# GD32E51x_CL register map
File version: 1.0
CPU: CM33 r0p4, little endian, MPU, FPU, 4 interrupt priority bits
Registers are 32-bit, read-write, reset 0x0 unless marked. A register's access mark holds for its fields unless they carry their own. Offsets are from the block's base; [hi:lo] are bit positions; {n}, {i} and the like mark numbered series; 'fields as' and 'values as' point back to an identical list.

## EXMC — External memory controller
Base 0xA0000000
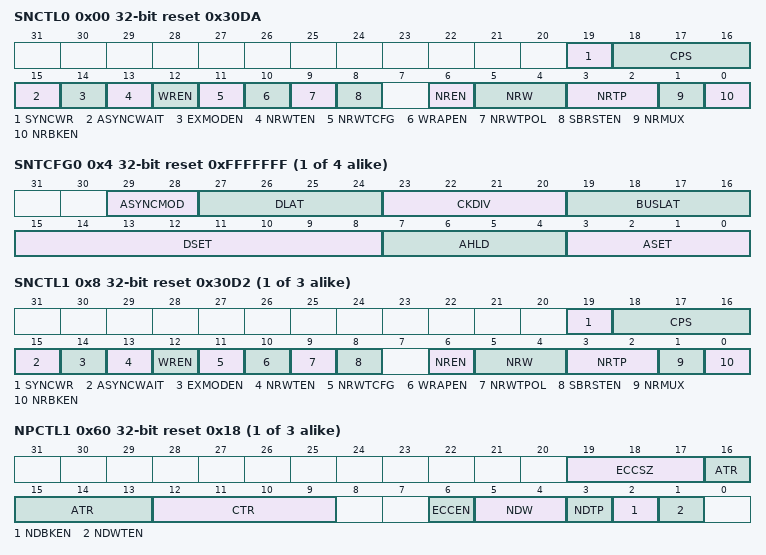
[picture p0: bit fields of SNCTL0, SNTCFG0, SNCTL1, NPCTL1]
0x00 SNCTL0 reset 0x30DA — SRAM/NOR flash control register 0
  [19] SYNCWR — Synchronous write
  [18:16] CPS — CRAM page size
  [15] ASYNCWAIT — Asynchronous wait
  [14] EXMODEN — Extended mode enable
  [13] NRWTEN — NWAIT signal enable
  [12] WREN — Write enable
  [11] NRWTCFG — NWAIT signal configuration, only work in synchronous mode
  [10] WRAPEN — Wrapped burst mode enable
  [9] NRWTPOL — NWAIT signal polarity
  [8] SBRSTEN — Synchronous burst enable
  [6] NREN — NOR Flash access enable
  [5:4] NRW — NOR bank memory data bus width
  [3:2] NRTP — NOR bank memory type
  [1] NRMUX — NOR bank memory address/data multiplexing
  [0] NRBKEN — NOR bank enable
{0x4+8i} SNTCFG{i} reset 0xFFFFFFF (i=0..3) — SRAM/NOR flash timing configuration register {i}
  [29:28] ASYNCMOD — Asynchronous access mode
  [27:24] DLAT — Data latency for NOR Flash
  [23:20] CKDIV — Synchronous clock divide ratio
  [19:16] BUSLAT — Bus latency
  [15:8] DSET — Data setup time
  [7:4] AHLD — Address hold time
  [3:0] ASET — Address setup time
{0x0+8i} SNCTL{i} reset 0x30D2 (i=1..3) — SRAM/NOR flash control register {i}
  fields as SNCTL0
{0x40+0x20*i} NPCTL{i} reset 0x18 (i=1..3) — NAND flash/PC card control register {i}
  [19:17] ECCSZ — ECC size
  [16:13] ATR — ALE to RE delay
  [12:9] CTR — CLE to RE delay
  [6] ECCEN — ECC enable
  [5:4] NDW — NAND bank memory data bus width
  [3] NDTP — NAND bank memory type
  [2] NDBKEN — NAND bank enable
  [1] NDWTEN — Wait feature enable
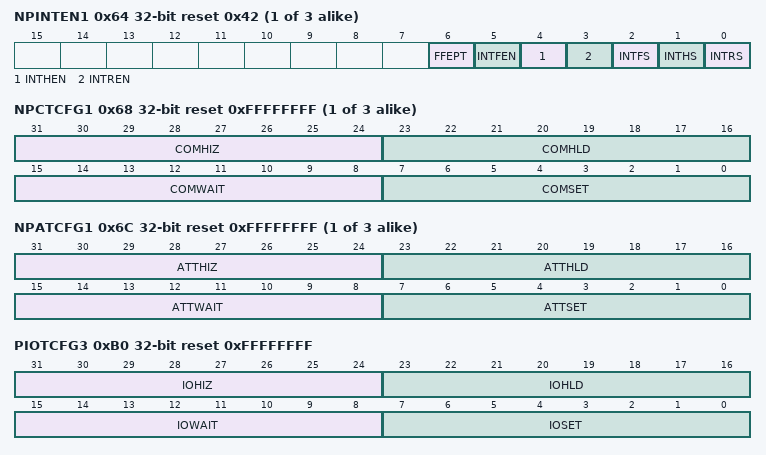
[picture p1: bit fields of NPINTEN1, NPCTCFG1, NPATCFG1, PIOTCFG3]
{0x44+0x20*i} NPINTEN{i} reset 0x42 (i=1..3) — NAND flash/PC card interrupt enable register {i}
  [6] FFEPT — FIFO empty flag
  [5] INTFEN — Interrupt falling edge detection enable
  [4] INTHEN — Interrupt high-level detection enable
  [3] INTREN — Interrupt rising edge detection enable bit
  [2] INTFS — Interrupt falling edge status
  [1] INTHS — Interrupt high-level status
  [0] INTRS — Interrupt rising edge status
{0x48+0x20*i} NPCTCFG{i} reset 0xFFFFFFFF (i=1..3) — NAND flash/PC card common space timing configuration register {i}
  [31:24] COMHIZ — Common memory data bus HiZ time
  [23:16] COMHLD — Common memory hold time
  [15:8] COMWAIT — Common memory wait time
  [7:0] COMSET — Common memory setup time
{0x4C+0x20*i} NPATCFG{i} reset 0xFFFFFFFF (i=1..3) — NAND flash/PC card attribute space timing configuration register {i}
  [31:24] ATTHIZ — Attribute memory data bus HiZ time
  [23:16] ATTHLD — Attribute memory hold time
  [15:8] ATTWAIT — Attribute memory wait time
  [7:0] ATTSET — Attribute memory setup time
0x74 NECC1 ro — NAND flash ECC register 1
  [31:0] ECC — ECC result
0x94 NECC2 ro — NAND flash ECC register 2
  [31:0] ECC — ECC result
0xB0 PIOTCFG3 reset 0xFFFFFFFF — PC card I/O space timing configuration register
  [31:24] IOHIZ — IO space data bus HiZ time
  [23:16] IOHLD — IO space hold time
  [15:8] IOWAIT — IO space wait time
  [7:0] IOSET — IO space setup time
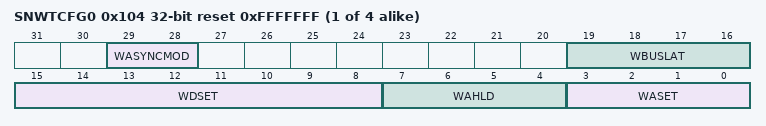
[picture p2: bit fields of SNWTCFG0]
{0x104+8i} SNWTCFG{i} reset 0xFFFFFFF (i=0..3) — SRAM/NOR flash write timing configuration register {i}
  [29:28] WASYNCMOD — Asynchronous access mode
  [19:16] WBUSLAT — Bus latency
  [15:8] WDSET — Data setup time
  [7:4] WAHLD — Address hold time
  [3:0] WASET — Address setup time

## EXTI — External interrupt/event controller
Base 0x40010400
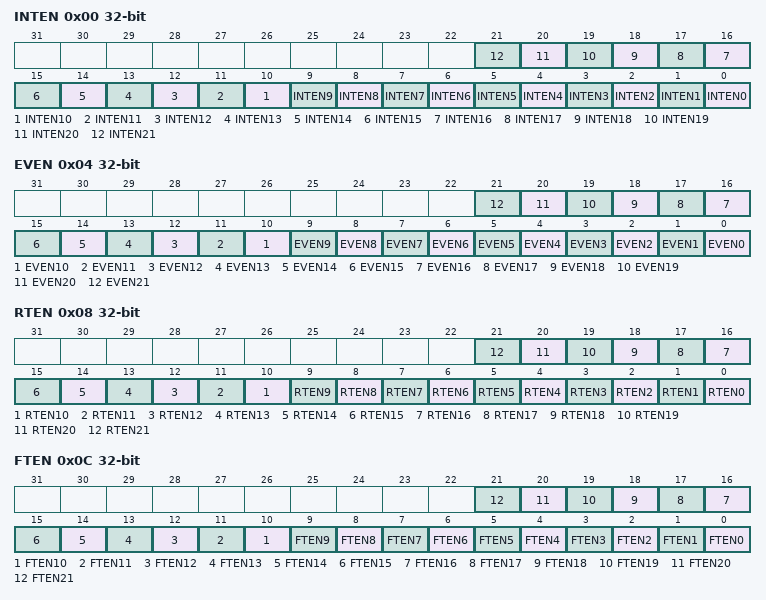
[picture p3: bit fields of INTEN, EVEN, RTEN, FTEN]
0x00 INTEN — Interrupt enable register (EXTI_INTEN)
  [n] INTEN{n} (n=0..21) — Enable Interrupt on line {n}
0x04 EVEN — Event enable register (EXTI_EVEN)
  [n] EVEN{n} (n=0..21) — Enable Event on line {n}
0x08 RTEN — Rising Edge Trigger Enable register (EXTI_RTEN)
  [n] RTEN{n} (n=0..21) — Rising edge trigger enable of line {n}
0x0C FTEN — Falling Egde Trigger Enable register (EXTI_FTEN)
  [n] FTEN{n} (n=0..21) — Falling edge trigger enable of line {n}
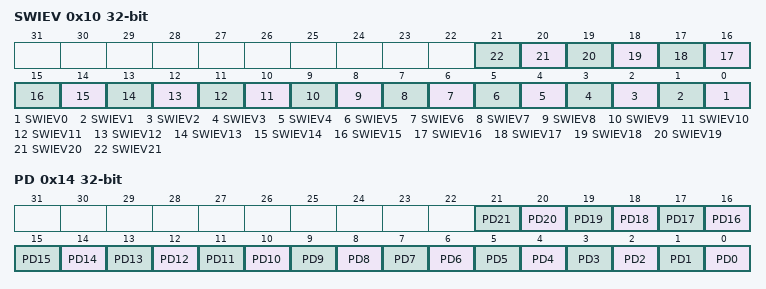
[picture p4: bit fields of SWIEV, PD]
0x10 SWIEV — Software interrupt event register (EXTI_SWIEV)
  [n] SWIEV{n} (n=0..21) — Interrupt/Event software trigger on line {n}
0x14 PD — Pending register (EXTI_PD)
  [n] PD{n} (n=0..21) — Interrupt pending status of line {n}
